VERSION ""

NS_ :

BS_:

BU_: ESP32 NavQPlus

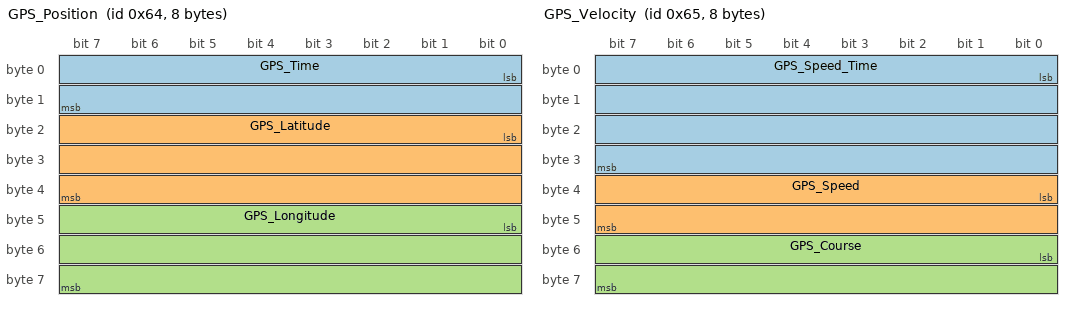
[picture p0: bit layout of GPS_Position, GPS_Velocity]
BO_ 100 GPS_Position: 8 ESP32
 SG_ GPS_Time : 0|16@1+ (1,0) [0|65535] "ms" NavQPlus
 SG_ GPS_Latitude : 16|24@1- (0.0001,0) [-90|90] "deg" NavQPlus
 SG_ GPS_Longitude : 40|24@1- (0.0001,0) [-180|180] "deg" NavQPlus

BO_ 101 GPS_Velocity: 8 ESP32
 SG_ GPS_Speed_Time : 0|32@1+ (1,0) [0|4294967295] "ms" NavQPlus
 SG_ GPS_Speed : 32|16@1+ (0.01,0) [0|655] "m/s" NavQPlus
 SG_ GPS_Course : 48|16@1+ (0.01,0) [0|360] "deg" NavQPlus

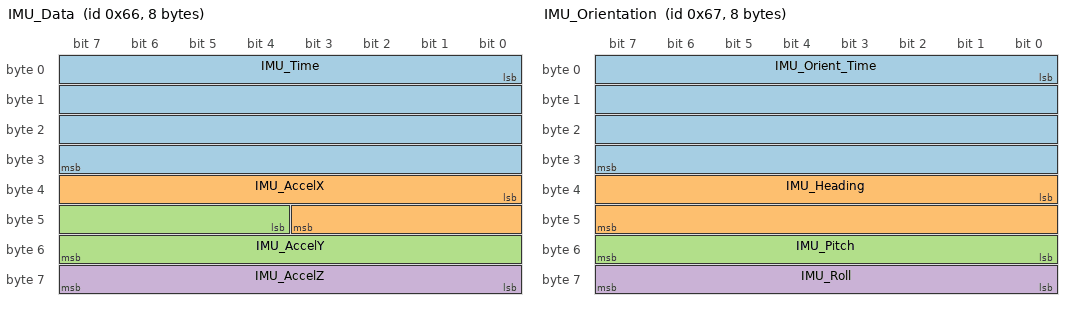
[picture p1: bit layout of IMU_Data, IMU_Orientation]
BO_ 102 IMU_Data: 8 ESP32
 SG_ IMU_Time : 0|32@1+ (1,0) [0|4294967295] "ms" NavQPlus
 SG_ IMU_AccelX : 32|12@1- (0.01,0) [-20|20] "m/s2" NavQPlus
 SG_ IMU_AccelY : 44|12@1- (0.01,0) [-20|20] "m/s2" NavQPlus
 SG_ IMU_AccelZ : 56|8@1- (0.1,0) [-12|12] "m/s2" NavQPlus

BO_ 103 IMU_Orientation: 8 ESP32
 SG_ IMU_Orient_Time : 0|32@1+ (1,0) [0|4294967295] "ms" NavQPlus
 SG_ IMU_Heading : 32|16@1+ (0.01,0) [0|360] "deg" NavQPlus
 SG_ IMU_Pitch : 48|8@1- (0.5,0) [-90|90] "deg" NavQPlus
 SG_ IMU_Roll : 56|8@1- (1,0) [-128|127] "deg" NavQPlus

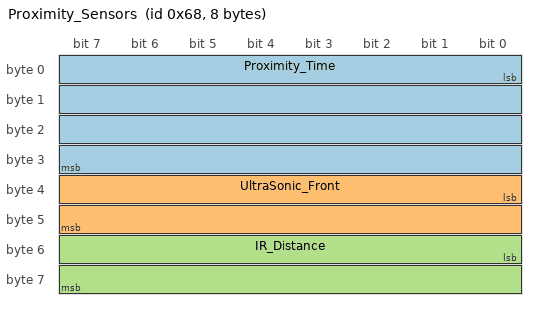
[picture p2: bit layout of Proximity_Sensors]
BO_ 104 Proximity_Sensors: 8 ESP32
 SG_ Proximity_Time : 0|32@1+ (1,0) [0|4294967295] "ms" NavQPlus
 SG_ UltraSonic_Front : 32|16@1+ (1,0) [0|65535] "mm" NavQPlus
 SG_ IR_Distance : 48|16@1+ (1,0) [0|65535] "mm" NavQPlus

CM_ BO_ 100 "GPS Position: Latitude and Longitude combined";
CM_ BO_ 101 "GPS Velocity: Speed and course over ground";
CM_ BO_ 102 "IMU linear acceleration on all three axes";
CM_ BO_ 103 "IMU orientation: heading, pitch, roll";
CM_ BO_ 104 "Proximity sensors: ultrasonic and IR";

CM_ SG_ 100 GPS_Latitude "Latitude in degrees, 0.0001 deg resolution (~11m)";
CM_ SG_ 100 GPS_Longitude "Longitude in degrees, 0.0001 deg resolution (~11m)";
CM_ SG_ 101 GPS_Speed "Speed over ground in m/s";
CM_ SG_ 101 GPS_Course "Course over ground in degrees";
CM_ SG_ 102 IMU_AccelX "X-axis acceleration, 0.01 m/s2 resolution";
CM_ SG_ 102 IMU_AccelY "Y-axis acceleration, 0.01 m/s2 resolution";
CM_ SG_ 102 IMU_AccelZ "Z-axis acceleration, 0.1 m/s2 resolution";
CM_ SG_ 103 IMU_Heading "Compass heading, 0.01 deg resolution";
CM_ SG_ 103 IMU_Pitch "Pitch angle, 0.5 deg resolution";
CM_ SG_ 103 IMU_Roll "Roll angle, 1 deg resolution";
CM_ SG_ 104 UltraSonic_Front "Front ultrasonic distance in mm";
CM_ SG_ 104 IR_Distance "IR distance in mm";

BA_DEF_ BO_ "GenMsgCycleTime" INT 0 10000;
BA_DEF_ "BusType" STRING;

BA_DEF_DEF_ "GenMsgCycleTime" 0;
BA_DEF_DEF_ "BusType" "CAN";

BA_ "GenMsgCycleTime" BO_ 100 100;
BA_ "GenMsgCycleTime" BO_ 101 100;
BA_ "GenMsgCycleTime" BO_ 102 20;
BA_ "GenMsgCycleTime" BO_ 103 50;
BA_ "GenMsgCycleTime" BO_ 104 50;
